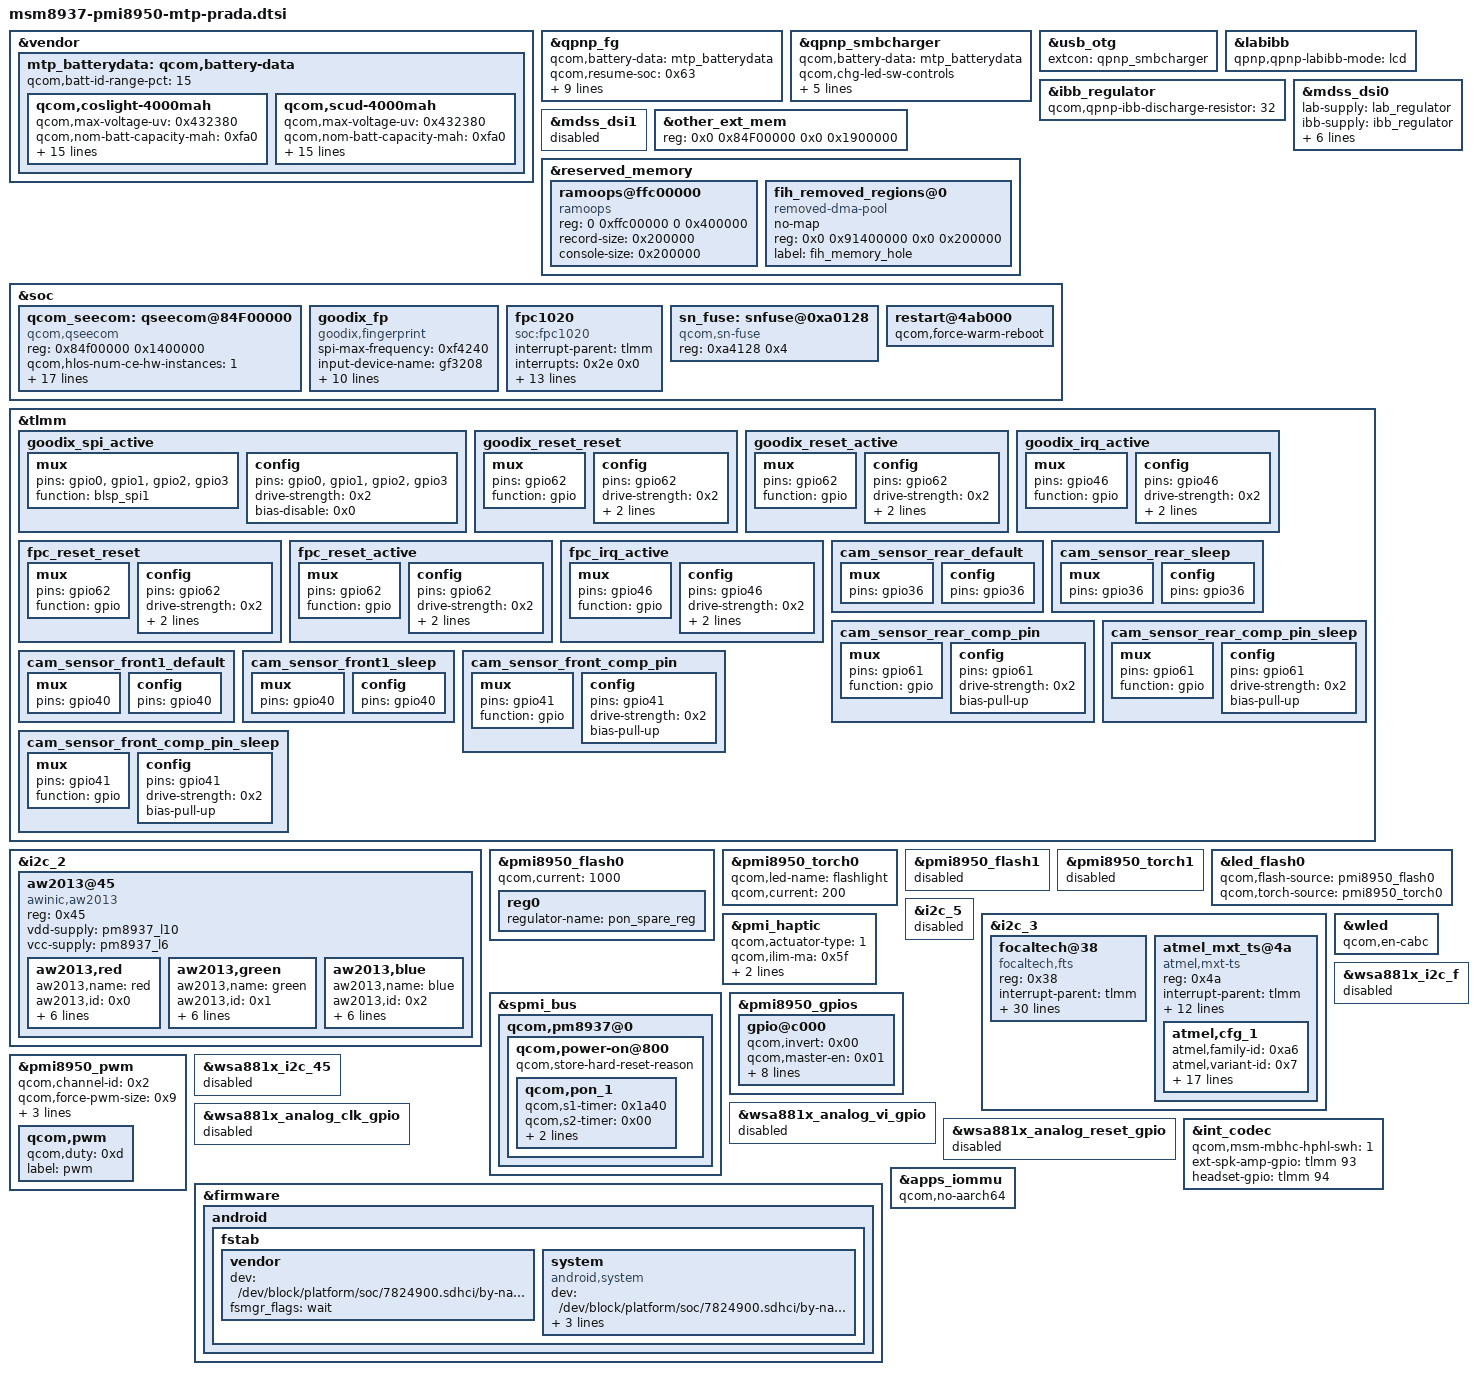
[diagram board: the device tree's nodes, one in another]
/*
 * Copyright (c) 2015-2016, 2018, The Linux Foundation. All rights reserved.
 *
 * This program is free software; you can redistribute it and/or modify
 * it under the terms of the GNU General Public License version 2 and
 * only version 2 as published by the Free Software Foundation.
 *
 * This program is distributed in the hope that it will be useful,
 * but WITHOUT ANY WARRANTY; without even the implied warranty of
 * MERCHANTABILITY or FITNESS FOR A PARTICULAR PURPOSE.  See the
 * GNU General Public License for more details.
 */

#include "pmi8950.dtsi"
#include "msm8937-mtp.dtsi"
#include "dsi-panel-prada.dtsi"

&vendor {
	mtp_batterydata: qcom,battery-data {
		qcom,batt-id-range-pct = <15>;
		qcom,coslight-4000mah {
			qcom,max-voltage-uv = <0x432380>;
			qcom,nom-batt-capacity-mah = <0xfa0>;
			qcom,v-cutoff-uv = <0x33e140>;
			qcom,chg-term-ua = <0x186a0>;
			qcom,batt-id-kohm = <0x64>;
			qcom,battery-beta = <0xd6b>;
			qcom,battery-type = "coslight_4000mah";
			qcom,chg-rslow-comp-c1 = <0x34f3b9>;
			qcom,chg-rslow-comp-c2 = <0x4d401f>;
			qcom,chg-rs-to-rslow = <0xc944b>;
			qcom,chg-rslow-comp-thr = <0xa8>;
			qcom,fastchg-current-ma = <0x7d0>;
			qcom,fg-cc-cv-threshold-mv = <0x1126>;
			qcom,checksum = <0xed34>;
			qcom,gui-version = "PMI8950GUI - 2.0.0.15";
			qcom,fg-profile-data = <0xee83497d 0x5881a277 0x5683a155 0x7781a88c 0xd82aa9a 0xcebdf3ca 0x5b0e0a88 0x177ece81 0x287c5683 0x7668417b 0xe8c4282 0xf89949bd 0x5cca5b0d 0x3c10aa5a 0x1470eefc 0x42359945 0xb400000 0x6f47df22 0xaf410000 0x0 0x0 0x8b6b6369 0x4760a989 0x5e7cc671 0x88588480 0xf975606b 0x205aa4a2 0x269060ec 0x5da0710c 0x2800ff36 0xf0113003 0xc>;
		};

		qcom,scud-4000mah {
			qcom,max-voltage-uv = <0x432380>;
			qcom,nom-batt-capacity-mah = <0xfa0>;
			qcom,v-cutoff-uv = <0x33e140>;
			qcom,chg-term-ua = <0x186a0>;
			qcom,batt-id-kohm = <0x32>;
			qcom,battery-beta = <0xd6b>;
			qcom,battery-type = "scud_4000mah";
			qcom,chg-rslow-comp-c1 = <0x283f20>;
			qcom,chg-rslow-comp-c2 = <0x2be6d3>;
			qcom,chg-rs-to-rslow = <0x1bacdf>;
			qcom,chg-rslow-comp-thr = <0x99>;
			qcom,fastchg-current-ma = <0x7d0>;
			qcom,fg-cc-cv-threshold-mv = <0x1126>;
			qcom,checksum = <0xd1a3>;
			qcom,gui-version = "PMI8950GUI - 2.0.0.15";
			qcom,fg-profile-data = <0xb883e475 0x717a996d 0x6f830e7c 0x36905c97 0x282299a 0xa8bcb4c8 0x4c136383 0x773c6b71 0xe1483e83 0x9078c584 0xad7b5682 0x699dbb7 0x11c8710c 0x6c100453 0x1470eefc 0x723c4947 0x36430000 0x6b47153a 0xfd1e0000 0x0 0x0 0x90732772 0xed67e380 0x5e751e63 0x594b0c73 0x396fe651 0xcf6b4eb0 0x21b56a98 0x6ca0710c 0x2800ff36 0xf0113003 0xc>;
		};
	};
};

&qpnp_fg {
	qcom,battery-data = <&mtp_batterydata>;
};

&qpnp_smbcharger {
	qcom,battery-data = <&mtp_batterydata>;
	qcom,chg-led-sw-controls;
	dpdm-supply = <&usb_otg>;
};

&usb_otg {
	extcon = <&qpnp_smbcharger>;
};

&labibb {
	status = "ok";
	qpnp,qpnp-labibb-mode = "lcd";
};

&ibb_regulator {
	qcom,qpnp-ibb-discharge-resistor = <32>;
};

&mdss_dsi0 {
	lab-supply = <&lab_regulator>;
	ibb-supply = <&ibb_regulator>;
	qcom,dsi-pref-prim-pan = <&dsi_hx8394f_boe_720p_video>;
	qcom,dsi-pref-sub-pan = <&dsi_ili9881c_tianma_720p_video>;
	qcom,dsi-pref-sub1-pan = <&dsi_nt35521s_ctc_720p_video>;
};

&mdss_dsi1 {
	status = "disabled";
};

&other_ext_mem {
	reg = <0x0 0x84F00000 0x0 0x1900000>;
};

&reserved_memory {
	ramoops@ffc00000 {
			compatible = "ramoops";
			reg = <0 0xffc00000 0 0x400000>;
			record-size = <0x200000>;
			console-size = <0x200000>;
	};

	fih_removed_regions@0 {
		compatible = "removed-dma-pool";
		no-map;
		reg = <0x0 0x91400000 0x0 0x200000>;
		label = "fih_memory_hole";
	};
};

&soc {
	/delete-node/ qseecom@85b00000;

	qcom_seecom: qseecom@84F00000 {
		compatible = "qcom,qseecom";
		reg = <0x84f00000 0x1400000>;
		reg-names = "secapp-region";
		qcom,hlos-num-ce-hw-instances = <1>;
		qcom,hlos-ce-hw-instance = <0>;
		qcom,qsee-ce-hw-instance = <0>;
		qcom,disk-encrypt-pipe-pair = <2>;
		qcom,support-fde;
		qcom,appsbl-qseecom-support;
		qcom,msm-bus,name = "qseecom-noc";
		qcom,msm-bus,num-cases = <4>;
		qcom,msm-bus,num-paths = <1>;
		qcom,support-bus-scaling;
		qcom,msm-bus,vectors-KBps =
			<55 512 0 0>,
			<55 512 0 0>,
			<55 512 120000 1200000>,
			<55 512 393600 3936000>;
		clocks = <&clock_gcc clk_crypto_clk_src>,
			 <&clock_gcc clk_gcc_crypto_clk>,
			 <&clock_gcc clk_gcc_crypto_ahb_clk>,
			 <&clock_gcc clk_gcc_crypto_axi_clk>;
		clock-names = "core_clk_src", "core_clk",
				"iface_clk", "bus_clk";
		qcom,ce-opp-freq = <100000000>;
	};
};

&tlmm {
	goodix_spi_active: goodix_spi_active {

		mux {
			pins = "gpio0", "gpio1", "gpio2", "gpio3";
			function = "blsp_spi1";
		};

		config {
			pins = "gpio0", "gpio1", "gpio2", "gpio3";
			drive-strength = <0x2>;
			bias-disable = <0x0>;
		};
	};

	goodix_reset_reset: goodix_reset_reset {

		mux {
			pins = "gpio62";
			function = "gpio";
		};

		config {
			pins = "gpio62";
			drive-strength = <0x2>;
			bias-disable = <0x0>;
			output-low;
		};
	};

	goodix_reset_active: goodix_reset_active {

		mux {
			pins = "gpio62";
			function = "gpio";
		};

		config {
			pins = "gpio62";
			drive-strength = <0x2>;
			bias-disable = <0x0>;
			output-high;
		};
	};

	goodix_irq_active: goodix_irq_active {

		mux {
			pins = "gpio46";
			function = "gpio";
		};

		config {
			pins = "gpio46";
			drive-strength = <0x2>;
			bias-disable = <0x0>;
			input-enable;
		};
	};

	fpc_reset_reset: fpc_reset_reset {

		mux {
			pins = "gpio62";
			function = "gpio";
		};

		config {
			pins = "gpio62";
			drive-strength = <0x2>;
			bias-disable = <0x0>;
			output-low;
		};
	};

	fpc_reset_active: fpc_reset_active {

		mux {
			pins = "gpio62";
			function = "gpio";
		};

		config {
			pins = "gpio62";
			drive-strength = <0x2>;
			bias-disable = <0x0>;
			output-high;
		};
	};

	fpc_irq_active: fpc_irq_active {

		mux {
			pins = "gpio46";
			function = "gpio";
		};

		config {
			pins = "gpio46";
			drive-strength = <0x2>;
			bias-disable = <0x0>;
			input-enable;
		};
	};
};

&tlmm {
	cam_sensor_rear_default {
		mux {
			pins = "gpio36";
		};
		config {
			pins = "gpio36";
		};
	};
	
	cam_sensor_rear_sleep {
		mux {
			pins = "gpio36";
		};
		config {
			pins = "gpio36";
		};
	};
	
	cam_sensor_rear_comp_pin: cam_sensor_rear_comp_pin {
		mux {
			pins = "gpio61";
			function = "gpio";
		};

		config {
			pins = "gpio61";
			drive-strength = <0x2>;
			bias-pull-up;
		};
	};

	cam_sensor_rear_comp_pin_sleep: cam_sensor_rear_comp_pin_sleep {
		mux {
			pins = "gpio61";
			function = "gpio";
		};

		config {
			pins = "gpio61";
			drive-strength = <0x2>;
			bias-pull-up;
		};
	};
	
	cam_sensor_front1_default {
		mux {
			pins = "gpio40";
		};
		config {
			pins = "gpio40";
		};
	};
	
	cam_sensor_front1_sleep {
		mux {
			pins = "gpio40";
		};
		config {
			pins = "gpio40";
		};
	};
	
	cam_sensor_front_comp_pin: cam_sensor_front_comp_pin {
		mux {
			pins = "gpio41";
			function = "gpio";
		};
		config {
			pins = "gpio41";
			drive-strength = <0x2>;
			bias-pull-up;
		};
	};

	cam_sensor_front_comp_pin_sleep: cam_sensor_front_comp_pin_sleep {
		mux {
			pins = "gpio41";
			function = "gpio";
		};

		config {
			pins = "gpio41";
			drive-strength = <0x2>;
			bias-pull-up;
		};
	};
};

&i2c_2 {
	status = "ok";
	aw2013@45 {
		compatible = "awinic,aw2013";
		reg = <0x45>;
		vdd-supply = <&pm8937_l10>;
		vcc-supply = <&pm8937_l6>;

		aw2013,red {
			aw2013,name = "red";
			aw2013,id = <0x0>;
			aw2013,max-brightness = <0xff>;
			aw2013,max-current = <0x2>;
			aw2013,rise-time-ms = <0x4>;
			aw2013,hold-time-ms = <0x0>;
			aw2013,fall-time-ms = <0x4>;
			aw2013,off-time-ms = <0x4>;
		};

		aw2013,green {
			aw2013,name = "green";
			aw2013,id = <0x1>;
			aw2013,max-brightness = <0xff>;
			aw2013,max-current = <0x2>;
			aw2013,rise-time-ms = <0x4>;
			aw2013,hold-time-ms = <0x0>;
			aw2013,fall-time-ms = <0x4>;
			aw2013,off-time-ms = <0x4>;
		};

		aw2013,blue {
			aw2013,name = "blue";
			aw2013,id = <0x2>;
			aw2013,max-brightness = <0xff>;
			aw2013,max-current = <0x2>;
			aw2013,rise-time-ms = <0x4>;
			aw2013,hold-time-ms = <0x0>;
			aw2013,fall-time-ms = <0x4>;
			aw2013,off-time-ms = <0x4>;
		};
	};
};

&pmi8950_flash0 {
	qcom,current = <1000>;
	reg0 {
		regulator-name = "pon_spare_reg";
	};
};

&pmi8950_torch0 {
	qcom,led-name = "flashlight";
	qcom,current = <200>;
};

&pmi8950_flash1 {
	status = "disabled";
};

&pmi8950_torch1 {
	status = "disabled";
};

&led_flash0 {
	/delete-property/ qcom,switch-source;
	qcom,flash-source = <&pmi8950_flash0>;
	qcom,torch-source = <&pmi8950_torch0>;
};
		
&soc {
	goodix_fp {
		compatible = "goodix,fingerprint";
		spi-max-frequency = <0xf4240>;
		input-device-name = "gf3208";
		interrupt-parent = <&tlmm>;
		interrupts = <0x2e 0x0>;
		goodix,gpio_reset = <&tlmm 62>;
		goodix,gpio_irq = <&tlmm 46>;
		clock-names = "iface_clk", "core_clk";
		clocks = <&clock_gcc clk_gcc_blsp1_ahb_clk>,
			<&clock_gcc clk_gcc_blsp1_qup1_spi_apps_clk>;
		pinctrl-names = "goodixfp_spi_active", "goodixfp_reset_reset", "goodixfp_reset_active", "goodixfp_irq_active";
		pinctrl-0 = <&goodix_spi_active>;
		pinctrl-1 = <&goodix_reset_reset>;
		pinctrl-2 = <&goodix_reset_active>;
		pinctrl-3 = <&goodix_irq_active>;
	};

	fpc1020 {
		compatible = "soc:fpc1020";
		interrupt-parent = <&tlmm>;
		interrupts = <0x2e 0x0>;
		fpc,gpio_rst = <&tlmm 62 0>;
		fpc,gpio_irq = <&tlmm 46 0>;
		vcc_spi-supply = <&pm8937_l5>;
		vdd_ana-supply = <&pm8937_l5>;
		vdd_io-supply = <&pm8937_l5>;
		fpc,enable-on-boot;
		fpc,enable-wakeup;
		fpc,spi-max-frequency = <0x493e00>;
		clock-names = "iface_clk", "core_clk";
		clocks = <&clock_gcc clk_gcc_blsp1_ahb_clk>,
				<&clock_gcc clk_gcc_blsp1_qup1_spi_apps_clk>;
		pinctrl-names = "fpc1020_reset_reset", "fpc1020_reset_active", "fpc1020_irq_active";
		pinctrl-0 = <&fpc_reset_reset>;
		pinctrl-1 = <&fpc_reset_active>;
		pinctrl-2 = <&fpc_irq_active>;
	};
};

&i2c_5 {
	status = "disabled";
};

&i2c_3 {
	status = "ok";
	focaltech@38 {
		compatible = "focaltech,fts";
		reg = <0x38>;
		interrupt-parent = <&tlmm>;
		interrupts = <0x41 0x0>;
		vdd-supply = <&pm8937_l10>;
		vcc_i2c-supply = <&pm8937_l6>;
		pinctrl-names = "pmx_ts_active", "pmx_ts_suspend", "pmx_ts_release";
		pinctrl-0 = <&ts_int_active &ts_reset_active>;
		pinctrl-1 = <&ts_int_suspend &ts_reset_suspend>;
		pinctrl-2 = <&ts_release>;
		focaltech,name = "focaltech";
		focaltech,family-id = <0x14>;
		focaltech,reset-gpio = <&tlmm 0x40 0x0>;
		focaltech,irq-gpio = <&tlmm 0x41 0x0>;
		focaltech,display-coords = <0x0 0x0 0x2d0 0x500>;
		focaltech,panel-coords = <0x0 0x0 0x2d0 0x500>;
		focaltech,button-map = <0xb4 0x21c 0x384>;
		focaltech,no-force-update;
		focaltech,i2c-pull-up;
		focaltech,group-id = <0x1>;
		focaltech,hard-reset-delay-ms = <0x14>;
		focaltech,soft-reset-delay-ms = <0x96>;
		focaltech,num-max-touches = <0xa>;
		focaltech,fw-name = "FT_Upgrade_App.i";
		focaltech,fw-delay-aa-ms = <0x1e>;
		focaltech,fw-delay-55-ms = <0x1e>;
		focaltech,fw-upgrade-id1 = <0x79>;
		focaltech,fw-upgrade-id2 = <0x11>;
		focaltech,fw-delay-readid-ms = <0xa>;
		focaltech,fw-delay-era-flsh-ms = <0x7d0>;
		focaltech,fw-vkey-support = <0x1>;
		focaltech,fw-auto-cal;
		focaltech,psensor-support;
		focaltech,gesture-support;
	};
	
	atmel_mxt_ts@4a {
		compatible = "atmel,mxt-ts";
		reg = <0x4a>;
		interrupt-parent = <&tlmm>;
		interrupts = <0x41 0x2008>;
		vddio-supply = <&pm8937_l6>;
		vdd-supply = <&pm8937_l10>;
		pinctrl-names = "pmx_ts_active", "pmx_ts_suspend";
		pinctrl-0 = <&ts_int_active &ts_reset_active>;
		pinctrl-1 = <&ts_int_suspend &ts_reset_suspend>;
		atmel,reset-gpio = <&tlmm 0x40 0x0>;
		atmel,irq-gpio = <&tlmm 0x41 0x2008>;
		atmel,mxt-fw-name = "mxt_308u.enc";
		atmel,config-array-size = <0x1>;
		atmel,default-config = <0x0>;
		atmel,irqflags = <0x2008>;
		atmel,vendor-id-byte = [00 03];

		atmel,cfg_1 {
			atmel,family-id = <0xa6>;
			atmel,variant-id = <0x7>;
			atmel,version = <0x10>;
			atmel,build = <0xab>;
			atmel,rev-id = <0x2>;
			atmel,panel-id = <0x0>;
			atmel,mxt-cfg-name = "mxt_308u_b5_f.raw";
			atmel,vendor-id = <0x31 0x31>;
			atmel,key-codes = <0x9e 0xac 0x8b>;
			atmel,selfintthr-stylus = <0x0>;
			atmel,t71-tchthr-pos = <0x16>;
			atmel,self-chgtime-min = <0x0>;
			atmel,self-chgtime-max = <0x0>;
			atmel,mult-intthr-sensitive = <0xc>;
			atmel,mult-intthr-not-sensitive = <0x11>;
			atmel,atchthr-sensitive = <0x6>;
			atmel,mult-tchthr-sensitive = <0x0>;
			atmel,mult-tchthr-not-sensitive = <0x0>;
			atmel,wake-up-self-adcx = <0x10>;
		};
	};
};

&pmi_haptic {
	qcom,actuator-type = <1>;
	qcom,ilim-ma = < 0x5f >;
	qcom,vmax-mv = < 0xaf0 >;
	qcom,wave-play-rate-us = < 0x148f >;
};

&wled {
	/delete-property/ qcom,en-ext-pfet-sc-pro;
	qcom,en-cabc;
};


&spmi_bus {
	qcom,pm8937@0 {
		qcom,power-on@800 {
			qcom,store-hard-reset-reason;
			qcom,pon_1 {		
				qcom,s1-timer = < 0x1a40 >;
				qcom,s2-timer = < 0x00 >;
				qcom,s2-type = < 0x07 >;
				qcom,support-reset = < 0x01 >;
			};
		};
	};
};

&pmi8950_gpios {
	gpio@c000 {
		qcom,invert = < 0x00 >;
		qcom,master-en = < 0x01 >;
		qcom,mode = < 0x01 >;
		qcom,out-strength = < 0x01 >;
		qcom,out-type = < 0x00 >;
		qcom,pin-num = < 0x01 >;
		qcom,pull = < 0x05 >;
		qcom,src-sel = < 0x00 >;
		qcom,vin-sel = < 0x00 >;
		reg = < 0xc000 0x100 >;
		status = "okay";
	};
};

&soc {
	sn_fuse: snfuse@0xa0128 {
		compatible = "qcom,sn-fuse";
		reg = <0xa4128 0x4>;
		reg-names = "sn-base";
	};
};

&qpnp_smbcharger {
	qcom,iterm-ma = <0xc8>;
	qcom,float-voltage-mv = <0x1130>;
	qcom,fastchg-current-comp = <0x4b0>;
	qcom,float-voltage-comp = <0xb>;
};

&qpnp_fg {
	qcom,resume-soc = <0x63>;
	qcom,hold-soc-while-full;
	qcom,warm-bat-decidegc = <0x1c2>;
	qcom,cool-bat-decidegc = <0x64>;
	qcom,hot-bat-decidegc = <0x258>;
	qcom,cold-bat-decidegc = <0x0>;
	qcom,fg-iterm-ma = <0xfa>;
	qcom,fg-chg-iterm-ma = <0xc8>;
	qcom,fg-vbat-estimate-diff-mv = <0xc8>;
	qcom,fg-delta-soc = <0x1>;
};

&pmi8950_pwm {
	status = "okay";
	qcom,channel-id = <0x2>;
	qcom,force-pwm-size = <0x9>;
	qcom,mode-select = <0x0>;
	qcom,ramp-index = <0x0>;
	qcom,period = <0x1a>;
	qcom,pwm {
		qcom,duty = <0xd>;
		label = "pwm";
	};
};

&wsa881x_i2c_f {
        status = "disabled";
};

&wsa881x_i2c_45 {
        status = "disabled";
};

&wsa881x_analog_vi_gpio {
        status = "disabled";
};

&wsa881x_analog_clk_gpio {
        status = "disabled";
};

&wsa881x_analog_reset_gpio {
        status = "disabled";
};

&int_codec {
	qcom,msm-mbhc-hphl-swh = <1>;
	ext-spk-amp-gpio = <&tlmm 93 0>;
	headset-gpio = <&tlmm 94 0>;
	/delete-property/ asoc-wsa-codec-names;
	/delete-property/ asoc-wsa-codec-prefixes;
	/delete-property/ msm-vdd-wsa-switch-supply;
	/delete-property/ qcom,msm-vdd-wsa-switch-voltage;
	/delete-property/ qcom,msm-vdd-wsa-switch-current;
};

&firmware {
	android {
		/delete-node/ vbmeta;
		fstab {
			vendor {
				dev = "/dev/block/platform/soc/7824900.sdhci/by-name/cust";
				fsmgr_flags = "wait";
			};
			system {
				compatible = "android,system";
				dev = "/dev/block/platform/soc/7824900.sdhci/by-name/system";
				type = "ext4";
				mnt_flags = "ro,barrier=1,discard";
				fsmgr_flags = "wait";
				status = "ok";
			};
		};
	};
};

&soc {
	restart@4ab000 {
		qcom,force-warm-reboot;
	};
};

&apps_iommu {
	qcom,no-aarch64;
};
